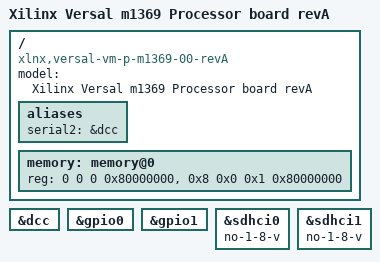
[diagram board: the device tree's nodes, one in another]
// SPDX-License-Identifier: GPL-2.0
/*
 * dts file for Xilinx Versal
 *
 * (C) Copyright 2024, Xilinx, Inc.
 *
 * Michal Simek <michal.simek@amd.com>
 */

#include "versal.dtsi"
#include "versal-clk.dtsi"

/ {
	compatible = "xlnx,versal-vm-p-m1369-00-revA",
		     "xlnx,versal-vm-p-m1369-00",
		     "xlnx,versal-vm-p-m1369", "xlnx,versal";
	model = "Xilinx Versal m1369 Processor board revA";

	aliases {
		serial2 = &dcc;
	};

	memory: memory@0 {
		device_type = "memory";
		reg = <0 0 0 0x80000000>, <0x8 0x0 0x1 0x80000000>;
	};
};

&dcc {
	status = "okay";
};

&gpio0 {
	status = "okay";
};

&gpio1 {
	status = "okay";
};

&sdhci0 {
	no-1-8-v;
};

&sdhci1 {
	no-1-8-v;
};
